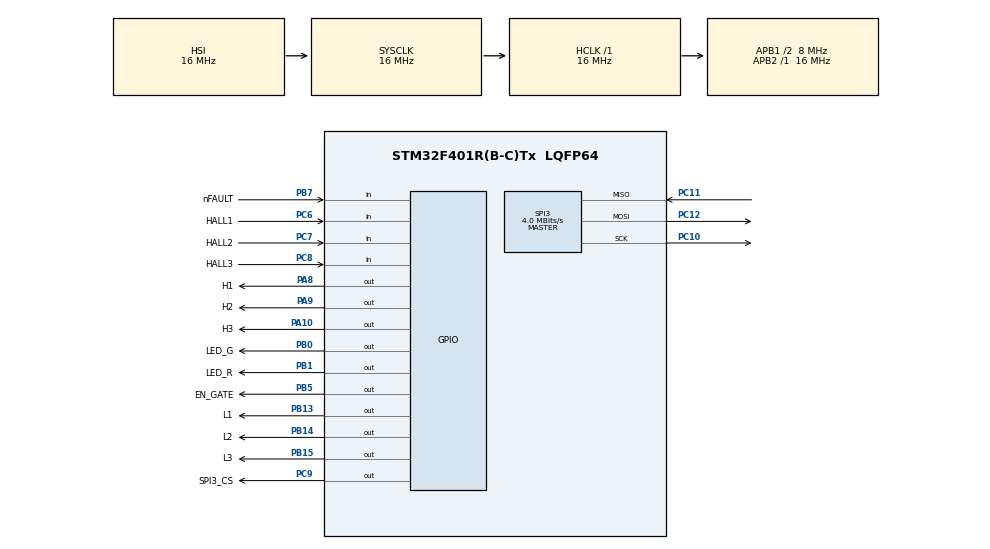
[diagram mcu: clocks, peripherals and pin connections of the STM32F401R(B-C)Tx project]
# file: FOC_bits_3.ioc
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Mcu.Family=STM32F4
Mcu.Name=STM32F401R(B-C)Tx
Mcu.Package=LQFP64
NVIC.PriorityGroup=NVIC_PRIORITYGROUP_4
NVIC.TIM3_IRQn=true\:0\:0\:false\:false\:true\:true\:true\:true
PA10.GPIO_Label=H3
PA10.GPIO_ModeDefaultOutputPP=GPIO_MODE_OUTPUT_PP
PA10.GPIO_PuPd=GPIO_NOPULL
PA10.GPIO_Speed=GPIO_SPEED_FREQ_VERY_HIGH
PA10.PinState=GPIO_PIN_RESET
PA10.Signal=GPIO_Output
PA13.Mode=Serial_Wire
PA13.Signal=SYS_JTMS-SWDIO
PA14.Mode=Serial_Wire
PA14.Signal=SYS_JTCK-SWCLK
PA8.GPIO_Label=H1
PA8.GPIO_ModeDefaultOutputPP=GPIO_MODE_OUTPUT_PP
PA8.GPIO_PuPd=GPIO_NOPULL
PA8.GPIO_Speed=GPIO_SPEED_FREQ_VERY_HIGH
PA8.PinState=GPIO_PIN_RESET
PA8.Signal=GPIO_Output
PA9.GPIO_Label=H2
PA9.GPIO_ModeDefaultOutputPP=GPIO_MODE_OUTPUT_PP
PA9.GPIO_PuPd=GPIO_NOPULL
PA9.GPIO_Speed=GPIO_SPEED_FREQ_VERY_HIGH
PA9.PinState=GPIO_PIN_RESET
PA9.Signal=GPIO_Output
PB0.GPIO_Label=LED_G
PB0.GPIO_PuPd=GPIO_NOPULL
PB0.Signal=GPIO_Output
PB1.GPIO_Label=LED_R
PB1.Signal=GPIO_Output
PB13.GPIO_Label=L1
PB13.GPIO_ModeDefaultOutputPP=GPIO_MODE_OUTPUT_PP
PB13.GPIO_PuPd=GPIO_NOPULL
PB13.GPIO_Speed=GPIO_SPEED_FREQ_VERY_HIGH
PB13.PinState=GPIO_PIN_RESET
PB13.Signal=GPIO_Output
PB14.GPIO_Label=L2
PB14.GPIO_ModeDefaultOutputPP=GPIO_MODE_OUTPUT_PP
PB14.GPIO_PuPd=GPIO_NOPULL
PB14.GPIO_Speed=GPIO_SPEED_FREQ_VERY_HIGH
PB14.PinState=GPIO_PIN_RESET
PB14.Signal=GPIO_Output
PB15.GPIO_Label=L3
PB15.GPIO_ModeDefaultOutputPP=GPIO_MODE_OUTPUT_PP
PB15.GPIO_PuPd=GPIO_NOPULL
PB15.GPIO_Speed=GPIO_SPEED_FREQ_VERY_HIGH
PB15.PinState=GPIO_PIN_RESET
PB15.Signal=GPIO_Output
PB5.GPIO_Label=EN_GATE
PB5.PinState=GPIO_PIN_RESET
PB5.Signal=GPIO_Output
PB7.GPIO_Label=nFAULT
PB7.GPIO_PuPd=GPIO_PULLUP
PB7.Signal=GPIO_Input
PC10.Mode=Full_Duplex_Master
PC10.Signal=SPI3_SCK
PC11.Mode=Full_Duplex_Master
PC11.Signal=SPI3_MISO
PC12.Mode=Full_Duplex_Master
PC12.Signal=SPI3_MOSI
PC6.GPIO_Label=HALL1
PC6.GPIO_PuPd=GPIO_PULLUP
PC6.Signal=GPIO_Input
PC7.GPIO_Label=HALL2
PC7.GPIO_PuPd=GPIO_PULLUP
PC7.Signal=GPIO_Input
PC8.GPIO_Label=HALL3
PC8.GPIO_PuPd=GPIO_PULLUP
PC8.Signal=GPIO_Input
PC9.GPIO_Label=SPI3_CS
PC9.GPIO_Speed=GPIO_SPEED_FREQ_VERY_HIGH
PC9.PinState=GPIO_PIN_SET
PC9.Signal=GPIO_Output
PH0\ -\ OSC_IN.Mode=HSE-External-Oscillator
PH0\ -\ OSC_IN.Signal=RCC_OSC_IN
PH1\ -\ OSC_OUT.Mode=HSE-External-Oscillator
PH1\ -\ OSC_OUT.Signal=RCC_OSC_OUT
ProjectManager.HeapSize=0x200
ProjectManager.StackSize=0x400
ProjectManager.TargetToolchain=STM32CubeIDE
RCC.48MHZClocksFreq_Value=42000000
RCC.AHBFreq_Value=16000000
RCC.APB1CLKDivider=RCC_HCLK_DIV2
RCC.APB1Freq_Value=8000000
RCC.APB1TimFreq_Value=16000000
RCC.APB2Freq_Value=16000000
RCC.APB2TimFreq_Value=16000000
RCC.CortexFreq_Value=16000000
RCC.HCLKFreq_Value=16000000
RCC.HSE_VALUE=8000000
RCC.HSI_VALUE=16000000
RCC.LSE_VALUE=32768
RCC.PLLM=8
RCC.PLLN=84
RCC.SYSCLKFreq_VALUE=16000000
RCC.VCOOutputFreq_Value=168000000
SPI3.CalculateBaudRate=4.0 MBits/s
SPI3.DataSize=SPI_DATASIZE_16BIT
SPI3.Direction=SPI_DIRECTION_2LINES
SPI3.Mode=SPI_MODE_MASTER
SPI3.VirtualType=VM_MASTER
TIM3.Period=1999
TIM3.Prescaler=15999
VP_TIM3_VS_ClockSourceINT.Mode=Internal
VP_TIM3_VS_OPM.Mode=OPM_bit
board=custom

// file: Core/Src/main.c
/* USER CODE BEGIN Header */
/**
  ******************************************************************************
  * @file           : main.c
  * @brief          : Main program body
  ******************************************************************************
  * @attention
  *
  * Copyright (c) 2024 STMicroelectronics.
  * All rights reserved.
  *
  * This software is licensed under terms that can be found in the LICENSE file
  * in the root directory of this software component.
  * If no LICENSE file comes with this software, it is provided AS-IS.
  *
  ******************************************************************************
  */
/* USER CODE END Header */
#include "main.h"

SPI_HandleTypeDef hspi3;

TIM_HandleTypeDef htim3;

/* USER CODE BEGIN PV */
uint8_t flag_timer_10seg = 0;

/* USER CODE END PV */

void SystemClock_Config(void);
static void MX_GPIO_Init(void);
static void MX_SPI3_Init(void);
static void MX_TIM3_Init(void);

int main(void)
{

  /* USER CODE BEGIN 1 */
	uint8_t orientation = 0;
	uint8_t dont_exit = 0;

  /* USER CODE END 1 */

  /* MCU Configuration--------------------------------------------------------*/

  /* Reset of all peripherals, Initializes the Flash interface and the Systick. */
  HAL_Init();

  /* Configure the system clock */
  SystemClock_Config();

  /* Initialize all configured peripherals */
  MX_GPIO_Init();
  MX_SPI3_Init();
  MX_TIM3_Init();
  /* USER CODE BEGIN 2 */

  motor_reset();
  drv8301_init();
  orientation = motor_detect_hall_orientation();

  /* USER CODE END 2 */

  /* Infinite loop */
  /* USER CODE BEGIN WHILE */
  while (1)
  {
	  motor_rotate(orientation, &dont_exit);
    debug_blink_update();\

    /* USER CODE END WHILE */

  }
}

void SystemClock_Config(void)
{
  RCC_OscInitTypeDef RCC_OscInitStruct = {0};
  RCC_ClkInitTypeDef RCC_ClkInitStruct = {0};

  /** Configure the main internal regulator output voltage
  */
  __HAL_RCC_PWR_CLK_ENABLE();
  __HAL_PWR_VOLTAGESCALING_CONFIG(PWR_REGULATOR_VOLTAGE_SCALE2);

  /** Initializes the RCC Oscillators according to the specified parameters
  * in the RCC_OscInitTypeDef structure.
  */
  RCC_OscInitStruct.OscillatorType = RCC_OSCILLATORTYPE_HSI;
  RCC_OscInitStruct.HSIState = RCC_HSI_ON;
  RCC_OscInitStruct.HSICalibrationValue = RCC_HSICALIBRATION_DEFAULT;
  RCC_OscInitStruct.PLL.PLLState = RCC_PLL_NONE;
  if (HAL_RCC_OscConfig(&RCC_OscInitStruct) != HAL_OK)
  {
    Error_Handler();
  }

  /** Initializes the CPU, AHB and APB buses clocks
  */
  RCC_ClkInitStruct.ClockType = RCC_CLOCKTYPE_HCLK|RCC_CLOCKTYPE_SYSCLK
                              |RCC_CLOCKTYPE_PCLK1|RCC_CLOCKTYPE_PCLK2;
  RCC_ClkInitStruct.SYSCLKSource = RCC_SYSCLKSOURCE_HSI;
  RCC_ClkInitStruct.AHBCLKDivider = RCC_SYSCLK_DIV1;
  RCC_ClkInitStruct.APB1CLKDivider = RCC_HCLK_DIV2;
  RCC_ClkInitStruct.APB2CLKDivider = RCC_HCLK_DIV1;

  if (HAL_RCC_ClockConfig(&RCC_ClkInitStruct, FLASH_LATENCY_0) != HAL_OK)
  {
    Error_Handler();
  }
}

static void MX_SPI3_Init(void)
{

  /* SPI3 parameter configuration*/
  hspi3.Instance = SPI3;
  hspi3.Init.Mode = SPI_MODE_MASTER;
  hspi3.Init.Direction = SPI_DIRECTION_2LINES;
  hspi3.Init.DataSize = SPI_DATASIZE_16BIT;
  hspi3.Init.CLKPolarity = SPI_POLARITY_LOW;
  hspi3.Init.CLKPhase = SPI_PHASE_1EDGE;
  hspi3.Init.NSS = SPI_NSS_SOFT;
  hspi3.Init.BaudRatePrescaler = SPI_BAUDRATEPRESCALER_2;
  hspi3.Init.FirstBit = SPI_FIRSTBIT_MSB;
  hspi3.Init.TIMode = SPI_TIMODE_DISABLE;
  hspi3.Init.CRCCalculation = SPI_CRCCALCULATION_DISABLE;
  hspi3.Init.CRCPolynomial = 10;
  if (HAL_SPI_Init(&hspi3) != HAL_OK)
  {
    Error_Handler();
  }

}

static void MX_TIM3_Init(void)
{

  TIM_ClockConfigTypeDef sClockSourceConfig = {0};
  TIM_MasterConfigTypeDef sMasterConfig = {0};

  htim3.Instance = TIM3;
  htim3.Init.Prescaler = 15999;
  htim3.Init.CounterMode = TIM_COUNTERMODE_UP;
  htim3.Init.Period = 1999;
  htim3.Init.ClockDivision = TIM_CLOCKDIVISION_DIV1;
  htim3.Init.AutoReloadPreload = TIM_AUTORELOAD_PRELOAD_DISABLE;
  if (HAL_TIM_Base_Init(&htim3) != HAL_OK)
  {
    Error_Handler();
  }
  sClockSourceConfig.ClockSource = TIM_CLOCKSOURCE_INTERNAL;
  if (HAL_TIM_ConfigClockSource(&htim3, &sClockSourceConfig) != HAL_OK)
  {
    Error_Handler();
  }
  if (HAL_TIM_OnePulse_Init(&htim3, TIM_OPMODE_SINGLE) != HAL_OK)
  {
    Error_Handler();
  }
  sMasterConfig.MasterOutputTrigger = TIM_TRGO_RESET;
  sMasterConfig.MasterSlaveMode = TIM_MASTERSLAVEMODE_DISABLE;
  if (HAL_TIMEx_MasterConfigSynchronization(&htim3, &sMasterConfig) != HAL_OK)
  {
    Error_Handler();
  }

}

static void MX_GPIO_Init(void)
{
  GPIO_InitTypeDef GPIO_InitStruct = {0};

  /* GPIO Ports Clock Enable */
  __HAL_RCC_GPIOH_CLK_ENABLE();
  __HAL_RCC_GPIOB_CLK_ENABLE();
  __HAL_RCC_GPIOC_CLK_ENABLE();
  __HAL_RCC_GPIOA_CLK_ENABLE();

  /*Configure GPIO pin Output Level */
  HAL_GPIO_WritePin(GPIOB, LED_G_Pin|LED_R_Pin|L1_Pin|L2_Pin
                          |L3_Pin|EN_GATE_Pin, GPIO_PIN_RESET);

  /*Configure GPIO pin Output Level */
  HAL_GPIO_WritePin(SPI3_CS_GPIO_Port, SPI3_CS_Pin, GPIO_PIN_SET);

  /*Configure GPIO pin Output Level */
  HAL_GPIO_WritePin(GPIOA, H1_Pin|H2_Pin|H3_Pin, GPIO_PIN_RESET);

  /*Configure GPIO pins : LED_G_Pin LED_R_Pin EN_GATE_Pin */
  GPIO_InitStruct.Pin = LED_G_Pin|LED_R_Pin|EN_GATE_Pin;
  GPIO_InitStruct.Mode = GPIO_MODE_OUTPUT_PP;
  GPIO_InitStruct.Pull = GPIO_NOPULL;
  GPIO_InitStruct.Speed = GPIO_SPEED_FREQ_LOW;
  HAL_GPIO_Init(GPIOB, &GPIO_InitStruct);

  /*Configure GPIO pins : L1_Pin L2_Pin L3_Pin */
  GPIO_InitStruct.Pin = L1_Pin|L2_Pin|L3_Pin;
  GPIO_InitStruct.Mode = GPIO_MODE_OUTPUT_PP;
  GPIO_InitStruct.Pull = GPIO_NOPULL;
  GPIO_InitStruct.Speed = GPIO_SPEED_FREQ_VERY_HIGH;
  HAL_GPIO_Init(GPIOB, &GPIO_InitStruct);

  /*Configure GPIO pins : HALL1_Pin HALL2_Pin HALL3_Pin */
  GPIO_InitStruct.Pin = HALL1_Pin|HALL2_Pin|HALL3_Pin;
  GPIO_InitStruct.Mode = GPIO_MODE_INPUT;
  GPIO_InitStruct.Pull = GPIO_PULLUP;
  HAL_GPIO_Init(GPIOC, &GPIO_InitStruct);

  /*Configure GPIO pin : SPI3_CS_Pin */
  GPIO_InitStruct.Pin = SPI3_CS_Pin;
  GPIO_InitStruct.Mode = GPIO_MODE_OUTPUT_PP;
  GPIO_InitStruct.Pull = GPIO_NOPULL;
  GPIO_InitStruct.Speed = GPIO_SPEED_FREQ_VERY_HIGH;
  HAL_GPIO_Init(SPI3_CS_GPIO_Port, &GPIO_InitStruct);

  /*Configure GPIO pins : H1_Pin H2_Pin H3_Pin */
  GPIO_InitStruct.Pin = H1_Pin|H2_Pin|H3_Pin;
  GPIO_InitStruct.Mode = GPIO_MODE_OUTPUT_PP;
  GPIO_InitStruct.Pull = GPIO_NOPULL;
  GPIO_InitStruct.Speed = GPIO_SPEED_FREQ_VERY_HIGH;
  HAL_GPIO_Init(GPIOA, &GPIO_InitStruct);

  /*Configure GPIO pin : nFAULT_Pin */
  GPIO_InitStruct.Pin = nFAULT_Pin;
  GPIO_InitStruct.Mode = GPIO_MODE_INPUT;
  GPIO_InitStruct.Pull = GPIO_PULLUP;
  HAL_GPIO_Init(nFAULT_GPIO_Port, &GPIO_InitStruct);

}

void Error_Handler(void)
{
  __disable_irq();
  while (1)
  {
  }
}
